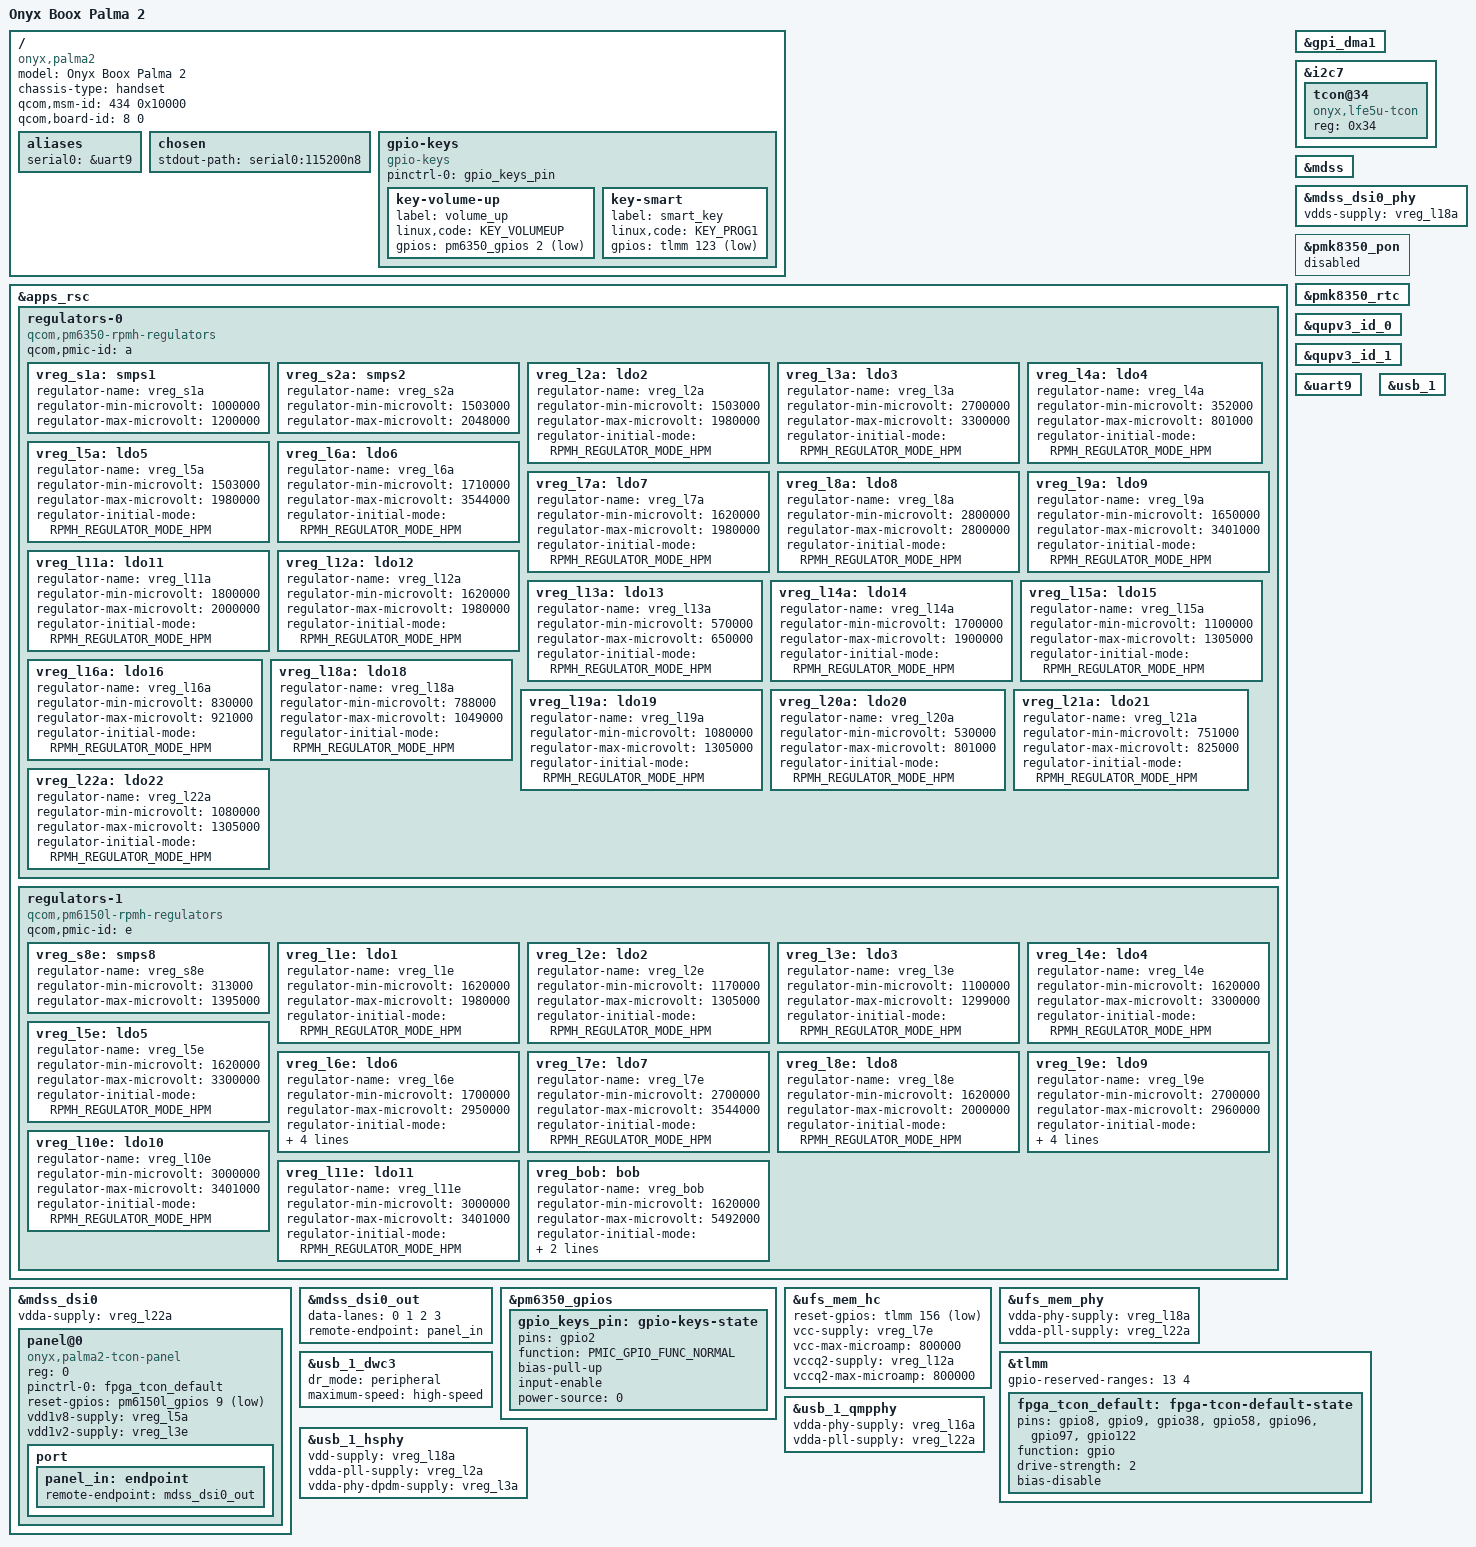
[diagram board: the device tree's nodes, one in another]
// SPDX-License-Identifier: BSD-3-Clause
/*
 * Onyx Boox Palma 2 (SM6350 "lagoon", board MTP P6). Derived from sm7225-fairphone-fp4.dts
 * (same PMIC set: PM6350, PM6150L, PM7250B, PMK8350; regulator ranges verified identical
 * against the stock Android DT, see recon/root/live.dts).
 *
 * Stage 1: boot + USB gadget. Stage 2: display (Lattice CertusPro-NX e-ink TCON on DSI0,
 * control port on I2C7 left to user space). Touch comes later.
 */
/dts-v1/;

/* PM7250B is configured to use SID2/3 */
#define PM7250B_SID 2
#define PM7250B_SID1 3
/* PMK8350 is configured to use SID6 instead of 0 */
#define PMK8350_SID 6

#include <dt-bindings/gpio/gpio.h>
#include <dt-bindings/input/input.h>
#include <dt-bindings/pinctrl/qcom,pmic-gpio.h>
#include <dt-bindings/regulator/qcom,rpmh-regulator.h>
#include "sm6350.dtsi"
#include "pm6150l.dtsi"
#include "pm6350.dtsi"
#include "pm7250b.dtsi"
#include "pmk8350.dtsi"

/ {
	model = "Onyx Boox Palma 2";
	compatible = "onyx,palma2", "qcom,sm6350";
	chassis-type = "handset";

	/* required for bootloader to select correct board */
	qcom,msm-id = <434 0x10000>;	/* SM6350 */
	qcom,board-id = <8 0>;		/* MTP, subtype 0 (stock DT) */

	aliases {
		serial0 = &uart9;
	};

	chosen {
		stdout-path = "serial0:115200n8";
	};

	gpio-keys {
		compatible = "gpio-keys";
		pinctrl-names = "default";
		pinctrl-0 = <&gpio_keys_pin>;

		key-volume-up {
			label = "volume_up";
			linux,code = <KEY_VOLUMEUP>;
			gpios = <&pm6350_gpios 2 GPIO_ACTIVE_LOW>;
		};

		/* side "smart" button, stock keycode 250 */
		key-smart {
			label = "smart_key";
			linux,code = <KEY_PROG1>;
			gpios = <&tlmm 123 GPIO_ACTIVE_LOW>;
		};
	};
};

&apps_rsc {
	regulators-0 {
		compatible = "qcom,pm6350-rpmh-regulators";
		qcom,pmic-id = "a";

		vreg_s1a: smps1 {
			regulator-name = "vreg_s1a";
			regulator-min-microvolt = <1000000>;
			regulator-max-microvolt = <1200000>;
		};

		vreg_s2a: smps2 {
			regulator-name = "vreg_s2a";
			regulator-min-microvolt = <1503000>;
			regulator-max-microvolt = <2048000>;
		};

		vreg_l2a: ldo2 {
			regulator-name = "vreg_l2a";
			regulator-min-microvolt = <1503000>;
			regulator-max-microvolt = <1980000>;
			regulator-initial-mode = <RPMH_REGULATOR_MODE_HPM>;
		};

		vreg_l3a: ldo3 {
			regulator-name = "vreg_l3a";
			regulator-min-microvolt = <2700000>;
			regulator-max-microvolt = <3300000>;
			regulator-initial-mode = <RPMH_REGULATOR_MODE_HPM>;
		};

		vreg_l4a: ldo4 {
			regulator-name = "vreg_l4a";
			regulator-min-microvolt = <352000>;
			regulator-max-microvolt = <801000>;
			regulator-initial-mode = <RPMH_REGULATOR_MODE_HPM>;
		};

		vreg_l5a: ldo5 {
			regulator-name = "vreg_l5a";
			regulator-min-microvolt = <1503000>;
			regulator-max-microvolt = <1980000>;
			regulator-initial-mode = <RPMH_REGULATOR_MODE_HPM>;
		};

		vreg_l6a: ldo6 {
			regulator-name = "vreg_l6a";
			regulator-min-microvolt = <1710000>;
			regulator-max-microvolt = <3544000>;
			regulator-initial-mode = <RPMH_REGULATOR_MODE_HPM>;
		};

		vreg_l7a: ldo7 {
			regulator-name = "vreg_l7a";
			regulator-min-microvolt = <1620000>;
			regulator-max-microvolt = <1980000>;
			regulator-initial-mode = <RPMH_REGULATOR_MODE_HPM>;
		};

		vreg_l8a: ldo8 {
			regulator-name = "vreg_l8a";
			regulator-min-microvolt = <2800000>;
			regulator-max-microvolt = <2800000>;
			regulator-initial-mode = <RPMH_REGULATOR_MODE_HPM>;
		};

		vreg_l9a: ldo9 {
			regulator-name = "vreg_l9a";
			regulator-min-microvolt = <1650000>;
			regulator-max-microvolt = <3401000>;
			regulator-initial-mode = <RPMH_REGULATOR_MODE_HPM>;
		};

		vreg_l11a: ldo11 {
			regulator-name = "vreg_l11a";
			regulator-min-microvolt = <1800000>;
			regulator-max-microvolt = <2000000>;
			regulator-initial-mode = <RPMH_REGULATOR_MODE_HPM>;
		};

		vreg_l12a: ldo12 {
			regulator-name = "vreg_l12a";
			regulator-min-microvolt = <1620000>;
			regulator-max-microvolt = <1980000>;
			regulator-initial-mode = <RPMH_REGULATOR_MODE_HPM>;
		};

		vreg_l13a: ldo13 {
			regulator-name = "vreg_l13a";
			regulator-min-microvolt = <570000>;
			regulator-max-microvolt = <650000>;
			regulator-initial-mode = <RPMH_REGULATOR_MODE_HPM>;
		};

		vreg_l14a: ldo14 {
			regulator-name = "vreg_l14a";
			regulator-min-microvolt = <1700000>;
			regulator-max-microvolt = <1900000>;
			regulator-initial-mode = <RPMH_REGULATOR_MODE_HPM>;
		};

		vreg_l15a: ldo15 {
			regulator-name = "vreg_l15a";
			regulator-min-microvolt = <1100000>;
			regulator-max-microvolt = <1305000>;
			regulator-initial-mode = <RPMH_REGULATOR_MODE_HPM>;
		};

		vreg_l16a: ldo16 {
			regulator-name = "vreg_l16a";
			regulator-min-microvolt = <830000>;
			regulator-max-microvolt = <921000>;
			regulator-initial-mode = <RPMH_REGULATOR_MODE_HPM>;
		};

		vreg_l18a: ldo18 {
			regulator-name = "vreg_l18a";
			regulator-min-microvolt = <788000>;
			regulator-max-microvolt = <1049000>;
			regulator-initial-mode = <RPMH_REGULATOR_MODE_HPM>;
		};

		vreg_l19a: ldo19 {
			regulator-name = "vreg_l19a";
			regulator-min-microvolt = <1080000>;
			regulator-max-microvolt = <1305000>;
			regulator-initial-mode = <RPMH_REGULATOR_MODE_HPM>;
		};

		vreg_l20a: ldo20 {
			regulator-name = "vreg_l20a";
			regulator-min-microvolt = <530000>;
			regulator-max-microvolt = <801000>;
			regulator-initial-mode = <RPMH_REGULATOR_MODE_HPM>;
		};

		vreg_l21a: ldo21 {
			regulator-name = "vreg_l21a";
			regulator-min-microvolt = <751000>;
			regulator-max-microvolt = <825000>;
			regulator-initial-mode = <RPMH_REGULATOR_MODE_HPM>;
		};

		vreg_l22a: ldo22 {
			regulator-name = "vreg_l22a";
			regulator-min-microvolt = <1080000>;
			regulator-max-microvolt = <1305000>;
			regulator-initial-mode = <RPMH_REGULATOR_MODE_HPM>;
		};
	};

	regulators-1 {
		compatible = "qcom,pm6150l-rpmh-regulators";
		qcom,pmic-id = "e";

		vreg_s8e: smps8 {
			regulator-name = "vreg_s8e";
			regulator-min-microvolt = <313000>;
			regulator-max-microvolt = <1395000>;
		};

		vreg_l1e: ldo1 {
			regulator-name = "vreg_l1e";
			regulator-min-microvolt = <1620000>;
			regulator-max-microvolt = <1980000>;
			regulator-initial-mode = <RPMH_REGULATOR_MODE_HPM>;
		};

		vreg_l2e: ldo2 {
			regulator-name = "vreg_l2e";
			regulator-min-microvolt = <1170000>;
			regulator-max-microvolt = <1305000>;
			regulator-initial-mode = <RPMH_REGULATOR_MODE_HPM>;
		};

		vreg_l3e: ldo3 {
			regulator-name = "vreg_l3e";
			regulator-min-microvolt = <1100000>;
			regulator-max-microvolt = <1299000>;
			regulator-initial-mode = <RPMH_REGULATOR_MODE_HPM>;
		};

		vreg_l4e: ldo4 {
			regulator-name = "vreg_l4e";
			regulator-min-microvolt = <1620000>;
			regulator-max-microvolt = <3300000>;
			regulator-initial-mode = <RPMH_REGULATOR_MODE_HPM>;
		};

		vreg_l5e: ldo5 {
			regulator-name = "vreg_l5e";
			regulator-min-microvolt = <1620000>;
			regulator-max-microvolt = <3300000>;
			regulator-initial-mode = <RPMH_REGULATOR_MODE_HPM>;
		};

		vreg_l6e: ldo6 {
			regulator-name = "vreg_l6e";
			regulator-min-microvolt = <1700000>;
			regulator-max-microvolt = <2950000>;
			regulator-initial-mode = <RPMH_REGULATOR_MODE_HPM>;
			regulator-allow-set-load;
			regulator-allowed-modes = <RPMH_REGULATOR_MODE_LPM
						   RPMH_REGULATOR_MODE_HPM>;
		};

		vreg_l7e: ldo7 {
			regulator-name = "vreg_l7e";
			regulator-min-microvolt = <2700000>;
			regulator-max-microvolt = <3544000>;
			regulator-initial-mode = <RPMH_REGULATOR_MODE_HPM>;
		};

		vreg_l8e: ldo8 {
			regulator-name = "vreg_l8e";
			regulator-min-microvolt = <1620000>;
			regulator-max-microvolt = <2000000>;
			regulator-initial-mode = <RPMH_REGULATOR_MODE_HPM>;
		};

		vreg_l9e: ldo9 {
			regulator-name = "vreg_l9e";
			regulator-min-microvolt = <2700000>;
			regulator-max-microvolt = <2960000>;
			regulator-initial-mode = <RPMH_REGULATOR_MODE_HPM>;
			regulator-allow-set-load;
			regulator-allowed-modes = <RPMH_REGULATOR_MODE_LPM
						   RPMH_REGULATOR_MODE_HPM>;
		};

		vreg_l10e: ldo10 {
			regulator-name = "vreg_l10e";
			regulator-min-microvolt = <3000000>;
			regulator-max-microvolt = <3401000>;
			regulator-initial-mode = <RPMH_REGULATOR_MODE_HPM>;
		};

		vreg_l11e: ldo11 {
			regulator-name = "vreg_l11e";
			regulator-min-microvolt = <3000000>;
			regulator-max-microvolt = <3401000>;
			regulator-initial-mode = <RPMH_REGULATOR_MODE_HPM>;
		};

		vreg_bob: bob {
			regulator-name = "vreg_bob";
			regulator-min-microvolt = <1620000>;
			regulator-max-microvolt = <5492000>;
			regulator-initial-mode = <RPMH_REGULATOR_MODE_AUTO>;
			regulator-allow-bypass;
		};
	};
};

&gpi_dma1 {
	status = "okay";
};

&i2c7 {
	status = "okay";

	/*
	 * Lattice CertusPro-NX TCON control port (stock onyx,lfe5u_i2c). Deliberately no
	 * kernel driver: user space talks to it via /dev/i2c-N (tools/palma_epd_test.py).
	 */
	tcon@34 {
		compatible = "onyx,lfe5u-tcon";
		reg = <0x34>;
	};
};

&mdss {
	status = "okay";
};

&mdss_dsi0 {
	vdda-supply = <&vreg_l22a>;
	status = "okay";

	panel@0 {
		compatible = "onyx,palma2-tcon-panel";
		reg = <0>;

		pinctrl-names = "default";
		pinctrl-0 = <&fpga_tcon_default>;

		/* DSI panel reset (stock qcom,platform-reset-gpio, sequence 1/0/1 x 10 ms) */
		reset-gpios = <&pm6150l_gpios 9 GPIO_ACTIVE_LOW>;

		/* FPGA TCON rails and sysCONFIG pins (stock lfcpnx@0 on spi2) */
		vdd1v8-supply = <&vreg_l5a>;
		vdd1v2-supply = <&vreg_l3e>;	/* PROGRAMN */		/* DONE; INITN is tlmm 9, unused */

		port {
			panel_in: endpoint {
				remote-endpoint = <&mdss_dsi0_out>;
			};
		};
	};
};

&mdss_dsi0_out {
	data-lanes = <0 1 2 3>;
	remote-endpoint = <&panel_in>;
};

&mdss_dsi0_phy {
	vdds-supply = <&vreg_l18a>;
	status = "okay";
};

&pm6350_gpios {
	gpio_keys_pin: gpio-keys-state {
		pins = "gpio2";
		function = PMIC_GPIO_FUNC_NORMAL;
		bias-pull-up;
		input-enable;
		power-source = <0>;
	};
};

&pmk8350_pon {
	status = "disabled";
};

&pmk8350_rtc {
	status = "okay";
};

&qupv3_id_0 {
	status = "okay";
};

&qupv3_id_1 {
	status = "okay";
};

&uart9 {
	status = "okay";
};

&ufs_mem_hc {
	reset-gpios = <&tlmm 156 GPIO_ACTIVE_LOW>;

	vcc-supply = <&vreg_l7e>;
	vcc-max-microamp = <800000>;
	vccq2-supply = <&vreg_l12a>;
	vccq2-max-microamp = <800000>;

	status = "okay";
};

&ufs_mem_phy {
	vdda-phy-supply = <&vreg_l18a>;
	vdda-pll-supply = <&vreg_l22a>;

	status = "okay";
};

&tlmm {
	/* 13-16: fingerprint SPI (secure). FP4 also reserves 56-57, but on Palma 2 those are the FPGA SPI pins. */
	gpio-reserved-ranges = <13 4>;

	/* stock lfe5u_gpios / _power / _pram: plain gpio, 2 mA, no bias */
	fpga_tcon_default: fpga-tcon-default-state {
		pins = "gpio8", "gpio9", "gpio38", "gpio58", "gpio96", "gpio97", "gpio122";
		function = "gpio";
		drive-strength = <2>;
		bias-disable;
	};
};

&usb_1 {
	status = "okay";
};

&usb_1_dwc3 {
	/* stage 1: plain gadget, no Type-C role switching yet */
	dr_mode = "peripheral";
	maximum-speed = "high-speed";
};

&usb_1_hsphy {
	vdd-supply = <&vreg_l18a>;
	vdda-pll-supply = <&vreg_l2a>;
	vdda-phy-dpdm-supply = <&vreg_l3a>;

	status = "okay";
};

&usb_1_qmpphy {
	vdda-phy-supply = <&vreg_l16a>;
	vdda-pll-supply = <&vreg_l22a>;

	status = "okay";
};
